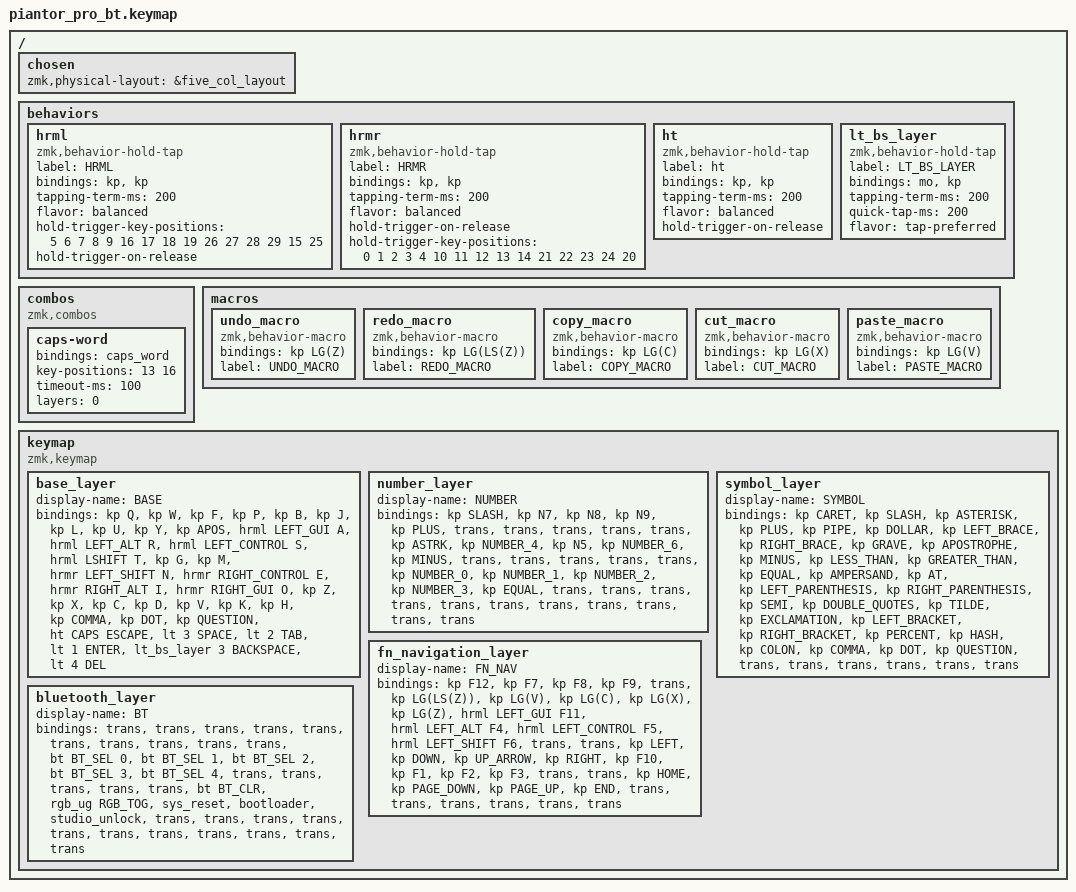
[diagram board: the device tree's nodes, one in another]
/*
 * Copyright (c) 2020 The ZMK Contributors
 *
 * SPDX-License-Identifier: MIT
 */

#include <behaviors.dtsi>
#include <dt-bindings/zmk/bt.h>
#include <dt-bindings/zmk/keys.h>
#include <dt-bindings/zmk/rgb.h>

/ {
    chosen { zmk,physical-layout = &five_col_layout; };
};

/ {
    behaviors {
        hrml: hrml {
            compatible = "zmk,behavior-hold-tap";
            label = "HRML";
            bindings = <&kp>, <&kp>;

            #binding-cells = <2>;
            tapping-term-ms = <200>;
            flavor = "balanced";
            hold-trigger-key-positions = <5 6 7 8 9 16 17 18 19 26 27 28 29 15 25>;
            hold-trigger-on-release;
        };

        hrmr: hrmr {
            compatible = "zmk,behavior-hold-tap";
            label = "HRMR";
            bindings = <&kp>, <&kp>;

            #binding-cells = <2>;
            tapping-term-ms = <200>;
            flavor = "balanced";
            hold-trigger-on-release;
            hold-trigger-key-positions = <0 1 2 3 4 10 11 12 13 14 21 22 23 24 20>;
        };

        ht: ht {
            compatible = "zmk,behavior-hold-tap";
            label = "ht";
            bindings = <&kp>, <&kp>;

            #binding-cells = <2>;
            tapping-term-ms = <200>;
            flavor = "balanced";
            hold-trigger-on-release;
        };

        lt_bs_layer: lt_bs_layer {
            compatible = "zmk,behavior-hold-tap";
            label = "LT_BS_LAYER";
            bindings = <&mo>, <&kp>;

            #binding-cells = <2>;
            tapping-term-ms = <200>;
            quick-tap-ms = <200>;
            flavor = "tap-preferred";
        };
    };

    combos {
        compatible = "zmk,combos";

        caps-word {
            bindings = <&caps_word>;
            key-positions = <13 16>;
            timeout-ms = <100>;
            layers = <0>;
        };
    };

    macros {
        undo_macro: undo_macro {
            compatible = "zmk,behavior-macro";
            #binding-cells = <0>;
            bindings = <&kp LG(Z)>;
            label = "UNDO_MACRO";
        };

        redo_macro: redo_macro {
            compatible = "zmk,behavior-macro";
            #binding-cells = <0>;
            bindings = <&kp LG(LS(Z))>;
            label = "REDO_MACRO";
        };

        copy_macro: copy_macro {
            compatible = "zmk,behavior-macro";
            #binding-cells = <0>;
            bindings = <&kp LG(C)>;
            label = "COPY_MACRO";
        };

        cut_macro: cut_macro {
            compatible = "zmk,behavior-macro";
            #binding-cells = <0>;
            bindings = <&kp LG(X)>;
            label = "CUT_MACRO";
        };

        paste_macro: paste_macro {
            compatible = "zmk,behavior-macro";
            #binding-cells = <0>;
            bindings = <&kp LG(V)>;
            label = "PASTE_MACRO";
        };
    };

    keymap {
        compatible = "zmk,keymap";

        base_layer {
            display-name = "BASE";

            // --------------------------------------------------------------
            // |  Q  |  W  |  E  |  R  |  T  |  Y  |  U   |  I  |  O  |  P  |
            // |  A  |  S  |  D  |  F  |  G  |  H  |  J   |  K  |  L  |  ;  |
            // |  Z  |  X  |  C  |  V  |  B  |  N  |  M   |  ,  |  .  |  /  |
            //                    | GUI | LWR | SPC | ENT | RSE  | ALT |

            bindings = <
  &kp Q  &kp W  &kp F  &kp P  &kp B  &kp J  &kp L  &kp U  &kp Y  &kp APOS      &hrml LEFT_GUI A  &hrml LEFT_ALT R  &hrml LEFT_CONTROL S  &hrml LSHIFT T  &kp G  &kp M  &hrmr LEFT_SHIFT N  &hrmr RIGHT_CONTROL E  &hrmr RIGHT_ALT I  &hrmr RIGHT_GUI O      &kp Z  &kp X  &kp C  &kp D  &kp V  &kp K  &kp H  &kp COMMA  &kp DOT  &kp QUESTION    &ht CAPS ESCAPE  &lt 3 SPACE  &lt 2 TAB  &lt 1 ENTER  &lt_bs_layer 3 BACKSPACE  &lt 4 DEL
            >;
        };

        number_layer {
            display-name = "NUMBER";

            // ---------------------------------------------------------------
            // |  1  |  2  |  3  |  4  |  5    |  6  |  7  |  8  |  9  |  0  |
            // | BT1 | BT2 | BT3 | BT4 | BT5   | LFT | DWN |  UP | RGT |     |
            // | BTCR| RGB | RST | BOOT| Unlock|     |     |     |     |     |
            //                    | GUI |     | SPC   | ENT |     | ALT |

            bindings = <
  &kp SLASH  &kp N7  &kp N8  &kp N9  &kp PLUS  &trans  &trans  &trans  &trans  &trans      &kp ASTRK  &kp NUMBER_4  &kp N5  &kp NUMBER_6  &kp MINUS  &trans  &trans  &trans  &trans  &trans      &kp NUMBER_0  &kp NUMBER_1  &kp NUMBER_2  &kp NUMBER_3  &kp EQUAL  &trans  &trans  &trans  &trans  &trans    &trans  &trans  &trans  &trans  &trans  &trans
            >;
        };

        symbol_layer {
            display-name = "SYMBOL";

            // -------------------------------------------------------------
            // |  !  |  @  |  #  |  $  |  %  |  ^  |  &  |  *  |  (  |  )  |
            // |     |     |     |     |     |  -  |  =  |  [  |  ]  |  \  |
            // |     |     |     |     |     |  _  |  +  |  {  |  }  | "|" |
            //                    | GUI |     | SPC | ENT |     | ALT |

            bindings = <
  &kp CARET  &kp SLASH  &kp ASTERISK  &kp PLUS  &kp PIPE  &kp DOLLAR  &kp LEFT_BRACE  &kp RIGHT_BRACE  &kp GRAVE  &kp APOSTROPHE      &kp MINUS  &kp LESS_THAN  &kp GREATER_THAN  &kp EQUAL  &kp AMPERSAND  &kp AT  &kp LEFT_PARENTHESIS  &kp RIGHT_PARENTHESIS  &kp SEMI  &kp DOUBLE_QUOTES      &kp TILDE  &kp EXCLAMATION  &kp LEFT_BRACKET  &kp RIGHT_BRACKET  &kp PERCENT  &kp HASH  &kp COLON  &kp COMMA  &kp DOT  &kp QUESTION    &trans  &trans  &trans  &trans  &trans  &trans
            >;
        };

        fn_navigation_layer {
            display-name = "FN_NAV";
            bindings = <
  &kp F12  &kp F7  &kp F8  &kp F9  &trans  &kp LG(LS(Z))  &kp LG(V)  &kp LG(C)  &kp LG(X)  &kp LG(Z)      &hrml LEFT_GUI F11  &hrml LEFT_ALT F4  &hrml LEFT_CONTROL F5  &hrml LEFT_SHIFT F6  &trans  &trans  &kp LEFT  &kp DOWN  &kp UP_ARROW  &kp RIGHT      &kp F10  &kp F1  &kp F2  &kp F3  &trans  &trans  &kp HOME  &kp PAGE_DOWN  &kp PAGE_UP  &kp END    &trans  &trans  &trans  &trans  &trans  &trans
            >;
        };

        bluetooth_layer {
            display-name = "BT";
            bindings = <
  &trans  &trans  &trans  &trans  &trans  &trans  &trans  &trans  &trans  &trans      &bt BT_SEL 0  &bt BT_SEL 1  &bt BT_SEL 2  &bt BT_SEL 3  &bt BT_SEL 4  &trans  &trans  &trans  &trans  &trans      &bt BT_CLR  &rgb_ug RGB_TOG  &sys_reset  &bootloader  &studio_unlock  &trans  &trans  &trans  &trans  &trans    &trans  &trans  &trans  &trans  &trans  &trans
            >;
        };
    };
};
